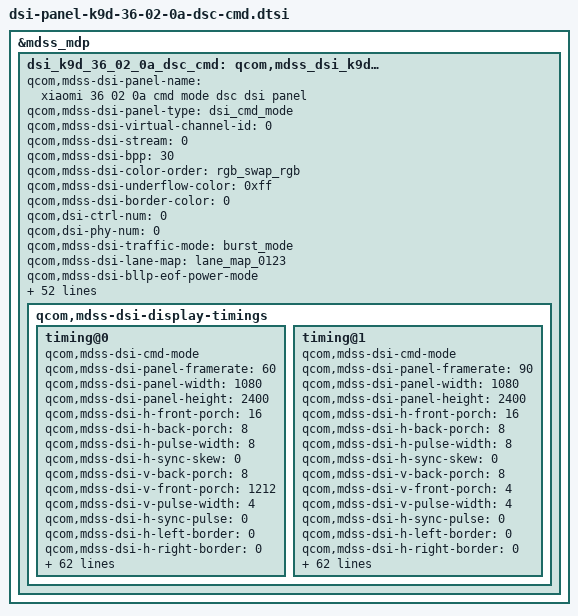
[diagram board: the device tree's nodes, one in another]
&mdss_mdp {
	dsi_k9d_36_02_0a_dsc_cmd: qcom,mdss_dsi_k9d_36_02_0a_dsc_cmd {
		qcom,mdss-dsi-panel-name = "xiaomi 36 02 0a cmd mode dsc dsi panel";
		qcom,mdss-dsi-panel-type = "dsi_cmd_mode";
		qcom,mdss-dsi-virtual-channel-id = <0>;
		qcom,mdss-dsi-stream = <0>;
		qcom,mdss-dsi-bpp = <30>;
		qcom,mdss-dsi-color-order = "rgb_swap_rgb";
		qcom,mdss-dsi-underflow-color = <0xff>;
		qcom,mdss-dsi-border-color = <0>;

		qcom,dsi-ctrl-num = <0>;
		qcom,dsi-phy-num = <0>;

		qcom,mdss-dsi-traffic-mode = "burst_mode";
		qcom,mdss-dsi-lane-map = "lane_map_0123";
		qcom,mdss-dsi-bllp-eof-power-mode;
		qcom,mdss-dsi-bllp-power-mode;
		qcom,mdss-dsi-lane-0-state;
		qcom,mdss-dsi-lane-1-state;
		qcom,mdss-dsi-lane-2-state;
		qcom,mdss-dsi-lane-3-state;
		qcom,mdss-dsi-dma-trigger = "trigger_sw";
		qcom,mdss-dsi-mdp-trigger = "none";
		qcom,mdss-dsi-reset-sequence =  <1 11>, <0 1>, <1 11>;
		qcom,mdss-pan-physical-width-dimension = <683>;
		qcom,mdss-pan-physical-height-dimension = <1517>;
		qcom,mdss-dsi-te-pin-select = <1>;
		qcom,mdss-dsi-wr-mem-start = <0x2c>;
		qcom,mdss-dsi-wr-mem-continue = <0x3c>;
		qcom,mdss-dsi-te-dcs-command = <1>;
		qcom,mdss-dsi-te-check-enable;
		qcom,mdss-dsi-te-using-te-pin;
		qcom,mdss-dsi-tx-eot-append;
		qcom,mdss-dsi-lp11-init;

		qcom,mdss-dsi-bl-inverted-dbv;
		qcom,bl-update-flag = "delay_until_first_frame";

		qcom,mdss-dsi-panel-hdr-enabled;
		qcom,mdss-dsi-panel-hdr-color-primaries = <14500 15500 32000 17000 15500 30000 8000 3000>;
		qcom,mdss-dsi-panel-peak-brightness = <4200000>;
		qcom,mdss-dsi-panel-blackness-level = <3230>;

		qcom,mdss-dsi-display-timings {
			timing@0{
				qcom,mdss-dsi-cmd-mode;
				qcom,mdss-dsi-panel-framerate = <60>;
				qcom,mdss-dsi-panel-width = <1080>;
				qcom,mdss-dsi-panel-height = <2400>;
				qcom,mdss-dsi-h-front-porch = <16>;
				qcom,mdss-dsi-h-back-porch = <8>;
				qcom,mdss-dsi-h-pulse-width = <8>;
				qcom,mdss-dsi-h-sync-skew = <0>;
				qcom,mdss-dsi-v-back-porch = <8>;
				qcom,mdss-dsi-v-front-porch = <1212>;
				qcom,mdss-dsi-v-pulse-width = <4>;
				qcom,mdss-dsi-h-sync-pulse = <0>;
				qcom,mdss-dsi-h-left-border = <0>;
				qcom,mdss-dsi-h-right-border = <0>;
				qcom,mdss-dsi-v-top-border = <0>;
				qcom,mdss-dsi-v-bottom-border = <0>;
				qcom,mdss-dsi-panel-clockrate = <682000000>;
				qcom,mdss-dsi-panel-jitter = <0x5 0x1>;
				qcom,mdss-mdp-transfer-time-us = <15700>;
				qcom,mdss-dsi-on-command = [
					/* Command Mode */
					39 01 00 00 00 00 06 F0 55 AA 52 08 00
					/* video trim */
					39 00 00 00 00 00 09 BA 01 E6 00 10 00 30 00 01
					15 00 00 00 00 00 02 B2 58
					15 00 00 00 00 00 02 6F 02
					/* 60Hz dimming speed: 12 frames*/
					39 00 00 00 00 00 03 B2 0C 0C
					/* ESD/MIPI Error Flag, Low when Error Happen */
					39 00 00 00 00 00 05 BE 0E 0B 14 13
					15 00 00 00 00 00 02 6F 05
					15 00 00 00 00 00 02 BE 8A
					15 00 00 00 00 00 02 C0 66
					15 00 00 00 00 00 02 6F 08
					15 01 00 00 00 00 02 B5 32
					/* Round Corner ON */
					39 00 00 00 00 00 06 F0 55 AA 52 08 07
					39 01 00 00 00 00 02 C0 01
					/* Adjustment of left corner */
					39 00 00 00 00 00 2C C1 30 0F 04 C9 0F 81 EE C6 3F FB B3 6A 3F F6 D1 42 80 00
					F7 33 B1 00 18 00 00 8B 23 33 C0 0F B9 0F DD 8D 00 00 00 0D 08 00 17 23 00
					39 00 00 00 00 00 2C C2 38 0F 0B 64 02 11 F6 4C 3F FA E2 14 FF FE 41 A8 00 00
					5E 26 90 00 00 24 00 17 90 33 C0 09 B4 0F 94 E9 00 00 90 0D 3C 90 17 57 00
					39 00 00 00 00 00 2C C3 3C 00 04 C9 0F 81 11 3A 3F F9 58 7C 00 04 F1 78 00 00
					00 00 00 90 18 3C 90 8B 5F 33 60 00 00 0C DD 73 00 00 04 20 08 04 2A 23 00
					39 01 00 00 00 00 2C C4 3C 00 0B 64 02 11 09 B4 3F F6 CA 24 C0 00 00 00 00 00
					00 00 00 80 00 CF 90 17 3B 33 C0 00 00 0C 94 17 00 00 94 20 3C 94 2A 57 00
					39 00 00 00 00 00 2C C5 26 00 04 C9 0F 81 11 3A 00 00 00 00 3F EF 14 34 80 00
					00 00 00 03 AC 00 04 1F 23 33 C0 00 00 03 23 8D 00 00 00 00 00 00 00 00 00
					39 00 00 00 00 00 2C C6 2E 00 0B 64 02 11 09 B4 00 03 11 F4 FF FD 62 7C 00 00
					00 00 00 04 20 24 04 37 90 33 C0 00 00 03 6C E9 00 00 00 00 00 00 00 00 00
					39 00 00 00 00 00 2C C7 2A 0F 04 C9 0F 81 EE C6 00 02 5A EE 00 0C AE 86 7F FD
					F9 F3 65 93 AC 3C 94 1F 5F 33 6F F0 47 00 23 73 00 00 00 00 00 00 00 00 00
					39 01 00 00 00 00 2C C8 2A 0F 0B 64 02 11 F6 4C 00 07 29 E4 C0 00 DF 2C 7F FF
					43 B2 E0 84 20 CF 94 37 3B 33 CF F6 4C 00 6C 17 00 00 00 00 00 00 00 00 00
					39 00 00 00 00 00 2C C9 27 00 03 C1 04 41 00 00 00 00 00 00 3F FE F8 42 00 00
					00 00 00 00 63 24 00 84 43 33 90 00 00 03 1F DF 00 00 00 00 00 00 00 00 00
					39 00 00 00 00 00 2C CA 21 00 03 C1 04 00 00 00 3F FF 0F C0 3F FF 08 00 00 00
					0F 04 00 00 42 24 00 62 43 33 90 03 E0 0F E1 E0 00 00 00 00 00 00 00 00 00
					39 00 00 00 00 00 2C CB 2D 00 04 00 04 00 00 00 3F FF 00 00 00 00 00 00 80 00
					00 00 00 00 42 44 00 62 64 33 60 00 00 0C E0 20 00 00 00 00 00 00 00 00 00
					39 01 00 00 00 00 2C CC 2B 00 04 00 04 41 00 00 00 00 00 00 00 00 00 00 FF FF
					EE FC 00 00 63 44 00 84 64 33 6F FB E0 00 20 21 00 00 00 00 00 00 00 00 00
					/* Adjustment of buttom line color */
					15 00 00 00 00 00 02 B4 C0
					15 00 00 00 00 00 02 6F 01
					39 01 00 00 00 00 04 B4 00 80 80
					/* Page 1 */
					39 01 00 00 00 00 06 F0 55 AA 52 08 01
					39 00 00 00 00 00 02 6F 01
					39 00 00 00 00 00 04 D2 00 00 11
					39 00 00 00 00 00 02 6F 06
					39 00 00 00 00 00 02 D2 05
					39 00 00 00 00 00 02 6F 0F
					39 00 00 00 00 00 02 D2 00
					//U_ELVDD discharge
					39 00 00 00 00 00 02 6F 09
					39 00 00 00 00 00 03 D2 00 00
					// U_ELVDD/U_ELVSS FD disable , AVDD FD enable
					39 00 00 00 00 00 02 CE 00
					//cmd3: aod no black
					39 00 00 00 00 00 05 FF AA 55 A5 80
					39 00 00 00 00 00 02 6F 61
					39 00 00 00 00 00 02 F3 80
					/* Page 0 */
					39 00 00 00 00 00 06 F0 55 AA 52 08 00
					39 00 00 00 00 00 02 C0 46
					//esd normal high without mipi error
					39 00 00 00 00 00 03 BE 0E 0B
					39 00 00 00 00 00 02 6F 05
					39 00 00 00 00 00 02 BE 88
					//PMIC normal FD en
					39 00 00 00 00 00 02 6F 08
					39 00 00 00 00 00 02 B5 32
					//PMIC AOD FD disable
					39 00 00 00 00 00 02 6F 0B
					39 00 00 00 00 00 04 B5 33 23 2B
					39 00 00 00 00 00 06 F0 55 AA 52 08 01
					39 00 00 00 00 00 04 D1 07 00 04
					39 00 00 00 00 00 05 3B 00 10 00 30
					/* Reduce source OP chopper offset */
					39 00 00 00 00 00 02 D9 C8
					/* VESA ON */
					15 01 00 00 00 00 02 90 01
					/* Choose VESA Edition */
					39 00 00 00 00 00 13 91
						AB 28 00 0C C2 00 03 1C 01 7E
						00 0F 08 BB 04 3D 10 F0
					/* DSC Setting */
					15 00 00 00 00 00 02 03 01
					/* Backlight */
					39 00 00 00 00 00 05 51 00 00 00 00
					/* Dimming on */
					15 00 00 00 00 00 02 53 20
					/* TE ON */
					15 00 00 00 00 00 02 35 00
					39 00 00 00 00 00 05 2A 00 00 04 37
					39 00 00 00 00 00 05 2B 00 00 09 5F
					/* Enter 60hz */
					15 01 00 00 00 00 02 2F 02
					/* OSC=109.2MHz */
					39 00 00 00 00 00 05 FF AA 55 A5 81
					15 00 00 00 00 00 02 6F 0F
					39 00 00 00 00 00 03 FD 01 5A
					/* OSC boost code */
					15 00 00 00 00 00 02 6F 04
					15 00 00 00 00 00 02 FD 5F
					15 00 00 00 00 00 02 6F 1A
					15 00 00 00 00 00 02 FD 5F
					05 01 00 00 00 00 01 2C
					/* Speed up code */
					39 00 00 00 00 00 06 F0 55 AA 52 08 00
					39 00 00 00 00 00 05 CA 12 00 92 02
					15 00 00 00 00 00 02 6F 02
					39 00 00 00 00 00 03 EC 80 10
					39 00 00 00 00 00 06 F0 55 AA 52 08 01
					39 00 00 00 00 00 03 CD 05 31
					15 00 00 00 00 00 02 6F 10
					15 00 00 00 00 00 02 D8 0C
					39 00 00 00 00 00 06 F0 55 AA 52 08 05
					39 00 00 00 00 00 03 B3 86 80
					39 00 00 00 00 00 03 B5 85 81
					39 00 00 00 00 00 05 B7 85 00 00 81
					39 00 00 00 00 00 05 B8 05 00 00 81
					39 00 00 00 00 00 03 EC 0D 11
					15 00 00 00 00 00 02 6F 02
					39 01 00 00 00 00 13 EC
						00 00 00 00 00 00 00 00 00 00
						00 00 00 00 00 00 00 00
					39 01 00 00 00 00 06 F0 55 AA 52 08 00
					//PMIC normal FD en
					39 01 00 00 00 00 02 6F 08
					39 01 00 00 00 00 02 B5 32
					//PMIC AOD FD disable
					39 01 00 00 00 00 02 6F 0B
					39 01 00 00 00 00 04 B5 33 23 2B
					39 01 00 00 00 00 06 F0 55 AA 52 08 01
					// U_ELVDD/U_ELVSS FD disable , AVDD FD disable
					39 01 00 00 00 00 02 CE 00
					/* Set page 1 */
					39 00 00 00 00 00 06 F0 55 AA 52 08 01
					/* Video trim */
					39 00 00 00 00 00 08 C3 94 01 97 D0 22 02 00
					/* Sleep Out */
					05 01 00 00 32 00 02 11 00
					/* Display On */
					05 01 00 00 10 00 02 29 00];
				qcom,mdss-dsi-off-command = [
					05 01 00 00 14 00 02 28 00
					05 01 00 00 50 00 02 10 00];
				qcom,mdss-dsi-on-command-state = "dsi_lp_mode";
				qcom,mdss-dsi-off-command-state = "dsi_lp_mode";

				qcom,mdss-dsi-timing-switch-command = [
					15 01 00 00 00 00 02 2F 02];
				qcom,mdss-dsi-timing-switch-command-state = "dsi_lp_mode";

				qcom,mdss-dsi-nolp-command = [
					15 01 00 00 00 00 02 65 00
					05 01 00 00 07 00 01 38
					39 01 00 00 00 00 06 F0 55 AA 52 08 01
					39 01 00 00 1B 00 05 BA 10 1A 10 1A
					39 01 00 00 00 00 05 BA 10 10 10 10
					15 01 00 00 00 00 02 2F 02];
				qcom,mdss-dsi-nolp-command-state = "dsi_lp_mode";

				qcom,compression-mode = "dsc";
				qcom,mdss-dsc-version = <0x11>;
				qcom,mdss-dsc-scr-version = <0x0>;
				qcom,mdss-dsc-slice-height = <12>;
				qcom,mdss-dsc-slice-width = <1080>;
				qcom,mdss-dsc-slice-per-pkt = <1>;
				qcom,mdss-dsc-bit-per-component = <10>;
				qcom,mdss-dsc-bit-per-pixel = <8>;
				qcom,mdss-dsc-block-prediction-enable;
			};

			timing@1{
				qcom,mdss-dsi-cmd-mode;
				qcom,mdss-dsi-panel-framerate = <90>;
				qcom,mdss-dsi-panel-width = <1080>;
				qcom,mdss-dsi-panel-height = <2400>;
				qcom,mdss-dsi-h-front-porch = <16>;
				qcom,mdss-dsi-h-back-porch = <8>;
				qcom,mdss-dsi-h-pulse-width = <8>;
				qcom,mdss-dsi-h-sync-skew = <0>;
				qcom,mdss-dsi-v-back-porch = <8>;
				qcom,mdss-dsi-v-front-porch = <4>;
				qcom,mdss-dsi-v-pulse-width = <4>;
				qcom,mdss-dsi-h-sync-pulse = <0>;
				qcom,mdss-dsi-h-left-border = <0>;
				qcom,mdss-dsi-h-right-border = <0>;
				qcom,mdss-dsi-v-top-border = <0>;
				qcom,mdss-dsi-v-bottom-border = <0>;
				qcom,mdss-dsi-panel-clockrate = <682000000>;
				qcom,mdss-dsi-panel-jitter = <0x5 0x1>;
				qcom,mdss-mdp-transfer-time-us = <9500>;
				qcom,mdss-dsi-on-command = [
					/* Command Mode */
					39 01 00 00 00 00 06 F0 55 AA 52 08 00
					/* video trim */
					39 00 00 00 00 00 09 BA 01 E6 00 10 00 30 00 01
					15 00 00 00 00 00 02 B2 58
					15 00 00 00 00 00 02 6F 02
					/* 90Hz dimming speed: 18 frames*/
					39 00 00 00 00 00 03 B2 12 12
					/* ESD/MIPI Error Flag, Low when Error Happen */
					39 00 00 00 00 00 05 BE 0E 0B 14 13
					15 00 00 00 00 00 02 6F 05
					15 00 00 00 00 00 02 BE 8A
					15 00 00 00 00 00 02 C0 66
					15 00 00 00 00 00 02 6F 08
					15 00 00 00 00 00 02 B5 32
					/* Round Corner ON */
					39 00 00 00 00 00 06 F0 55 AA 52 08 07
					39 01 00 00 00 00 02 C0 01
					/* Adjustment of left corner */
					39 00 00 00 00 00 2C C1 30 0F 04 C9 0F 81 EE C6 3F FB B3 6A 3F F6 D1 42 80 00
					F7 33 B1 00 18 00 00 8B 23 33 C0 0F B9 0F DD 8D 00 00 00 0D 08 00 17 23 00
					39 00 00 00 00 00 2C C2 38 0F 0B 64 02 11 F6 4C 3F FA E2 14 FF FE 41 A8 00 00
					5E 26 90 00 00 24 00 17 90 33 C0 09 B4 0F 94 E9 00 00 90 0D 3C 90 17 57 00
					39 00 00 00 00 00 2C C3 3C 00 04 C9 0F 81 11 3A 3F F9 58 7C 00 04 F1 78 00 00
					00 00 00 90 18 3C 90 8B 5F 33 60 00 00 0C DD 73 00 00 04 20 08 04 2A 23 00
					39 01 00 00 00 00 2C C4 3C 00 0B 64 02 11 09 B4 3F F6 CA 24 C0 00 00 00 00 00
					00 00 00 80 00 CF 90 17 3B 33 C0 00 00 0C 94 17 00 00 94 20 3C 94 2A 57 00
					39 00 00 00 00 00 2C C5 26 00 04 C9 0F 81 11 3A 00 00 00 00 3F EF 14 34 80 00
					00 00 00 03 AC 00 04 1F 23 33 C0 00 00 03 23 8D 00 00 00 00 00 00 00 00 00
					39 00 00 00 00 00 2C C6 2E 00 0B 64 02 11 09 B4 00 03 11 F4 FF FD 62 7C 00 00
					00 00 00 04 20 24 04 37 90 33 C0 00 00 03 6C E9 00 00 00 00 00 00 00 00 00
					39 00 00 00 00 00 2C C7 2A 0F 04 C9 0F 81 EE C6 00 02 5A EE 00 0C AE 86 7F FD
					F9 F3 65 93 AC 3C 94 1F 5F 33 6F F0 47 00 23 73 00 00 00 00 00 00 00 00 00
					39 01 00 00 00 00 2C C8 2A 0F 0B 64 02 11 F6 4C 00 07 29 E4 C0 00 DF 2C 7F FF
					43 B2 E0 84 20 CF 94 37 3B 33 CF F6 4C 00 6C 17 00 00 00 00 00 00 00 00 00
					39 00 00 00 00 00 2C C9 27 00 03 C1 04 41 00 00 00 00 00 00 3F FE F8 42 00 00
					00 00 00 00 63 24 00 84 43 33 90 00 00 03 1F DF 00 00 00 00 00 00 00 00 00
					39 00 00 00 00 00 2C CA 21 00 03 C1 04 00 00 00 3F FF 0F C0 3F FF 08 00 00 00
					0F 04 00 00 42 24 00 62 43 33 90 03 E0 0F E1 E0 00 00 00 00 00 00 00 00 00
					39 00 00 00 00 00 2C CB 2D 00 04 00 04 00 00 00 3F FF 00 00 00 00 00 00 80 00
					00 00 00 00 42 44 00 62 64 33 60 00 00 0C E0 20 00 00 00 00 00 00 00 00 00
					39 01 00 00 00 00 2C CC 2B 00 04 00 04 41 00 00 00 00 00 00 00 00 00 00 FF FF
					EE FC 00 00 63 44 00 84 64 33 6F FB E0 00 20 21 00 00 00 00 00 00 00 00 00
					/* Adjustment of buttom line color */
					15 00 00 00 00 00 02 B4 C0
					15 00 00 00 00 00 02 6F 01
					39 01 00 00 00 00 04 B4 00 80 80
					/* Page 1 */
					39 01 00 00 00 00 06 F0 55 AA 52 08 01
					39 00 00 00 00 00 02 6F 01
					39 00 00 00 00 00 04 D2 00 00 11
					39 00 00 00 00 00 02 6F 06
					39 00 00 00 00 00 02 D2 05
					39 00 00 00 00 00 02 6F 0F
					39 00 00 00 00 00 02 D2 00
					//U_ELVDD discharge
					39 00 00 00 00 00 02 6F 09
					39 00 00 00 00 00 03 D2 00 00
					// U_ELVDD/U_ELVSS FD disable , AVDD FD enable
					39 00 00 00 00 00 02 CE 00
					//cmd3: aod no black
					39 00 00 00 00 00 05 FF AA 55 A5 80
					39 00 00 00 00 00 02 6F 61
					39 00 00 00 00 00 02 F3 80
					/* Page 0 */
					39 00 00 00 00 00 06 F0 55 AA 52 08 00
					39 00 00 00 00 00 02 C0 46
					//esd normal high without mipi error
					39 00 00 00 00 00 03 BE 0E 0B
					39 00 00 00 00 00 02 6F 05
					39 00 00 00 00 00 02 BE 88
					//PMIC normal FD en
					39 00 00 00 00 00 02 6F 08
					39 00 00 00 00 00 02 B5 32
					//PMIC AOD FD disable
					39 00 00 00 00 00 02 6F 0B
					39 00 00 00 00 00 04 B5 33 23 2B
					39 00 00 00 00 00 06 F0 55 AA 52 08 01
					39 00 00 00 00 00 04 D1 07 00 04
					39 00 00 00 00 00 05 3B 00 10 00 30
					/* Reduce source OP chopper offset */
					39 00 00 00 00 00 02 D9 C8
					/* VESA ON */
					15 01 00 00 00 00 02 90 01
					/* Choose VESA Edition */
					39 00 00 00 00 00 13 91
						AB 28 00 0C C2 00 03 1C 01 7E
						00 0F 08 BB 04 3D 10 F0
					/* DSC setting */
					15 00 00 00 00 00 02 03 01
					/* Backlight */
					39 00 00 00 00 00 05 51 00 00 00 00
					/* Dimming On */
					15 00 00 00 00 00 02 53 20
					/* TE ON */
					15 00 00 00 00 00 02 35 00
					39 00 00 00 00 00 05 2A 00 00 04 37
					39 00 00 00 00 00 05 2B 00 00 09 5F
					/* Enter 90HZ */
					15 01 00 00 00 00 02 2F 01
					/* OSC=109.2MHz */
					39 00 00 00 00 00 05 FF AA 55 A5 81
					15 00 00 00 00 00 02 6F 0F
					39 00 00 00 00 00 03 FD 01 5A
					/* OSC boost code */
					15 00 00 00 00 00 02 6F 04
					15 00 00 00 00 00 02 FD 5F
					15 00 00 00 00 00 02 6F 1A
					15 00 00 00 00 00 02 FD 5F
					05 01 00 00 00 00 01 2C
					/* Speed up code */
					39 00 00 00 00 00 06 F0 55 AA 52 08 00
					39 00 00 00 00 00 05 CA 12 00 92 02
					15 00 00 00 00 00 02 6F 02
					39 00 00 00 00 00 03 EC 80 10
					39 00 00 00 00 00 06 F0 55 AA 52 08 01
					39 00 00 00 00 00 03 CD 05 31
					15 00 00 00 00 00 02 6F 10
					15 00 00 00 00 00 02 D8 0C
					39 00 00 00 00 00 06 F0 55 AA 52 08 05
					39 00 00 00 00 00 03 B3 86 80
					39 00 00 00 00 00 03 B5 85 81
					39 00 00 00 00 00 05 B7 85 00 00 81
					39 00 00 00 00 00 05 B8 05 00 00 81
					39 00 00 00 00 00 03 EC 0D 11
					15 00 00 00 00 00 02 6F 02
					39 01 00 00 00 00 13 EC
						00 00 00 00 00 00 00 00 00 00
						00 00 00 00 00 00 00 00
					39 01 00 00 00 00 06 F0 55 AA 52 08 00
					//PMIC normal FD en
					39 01 00 00 00 00 02 6F 08
					39 01 00 00 00 00 02 B5 32
					//PMIC AOD FD disable
					39 01 00 00 00 00 02 6F 0B
					39 01 00 00 00 00 04 B5 33 23 2B
					39 01 00 00 00 00 06 F0 55 AA 52 08 01
					// U_ELVDD/U_ELVSS FD disable , AVDD FD disable
					39 01 00 00 00 00 02 CE 00
					/* Set page 1 */
					39 00 00 00 00 00 06 F0 55 AA 52 08 01
					/* Video trim */
					39 00 00 00 00 00 08 C3 94 01 97 D0 22 02 00
					/* Sleep Out */
					05 01 00 00 32 00 02 11 00
					/* Display On */
					05 01 00 00 10 00 02 29 00];
				qcom,mdss-dsi-off-command = [
					05 01 00 00 14 00 02 28 00
					05 01 00 00 50 00 02 10 00];
				qcom,mdss-dsi-on-command-state = "dsi_lp_mode";
				qcom,mdss-dsi-off-command-state = "dsi_lp_mode";

				qcom,mdss-dsi-timing-switch-command = [
					15 01 00 00 00 00 02 2F 01];
				qcom,mdss-dsi-timing-switch-command-state = "dsi_lp_mode";

				qcom,mdss-dsi-nolp-command = [
					15 01 00 00 00 00 02 65 00
					05 01 00 00 07 00 01 38
					39 00 00 00 00 00 06 F0 55 AA 52 08 01
					39 01 00 00 1B 00 05 BA 10 1A 10 1A
					39 01 00 00 00 00 05 BA 10 10 10 10
					15 01 00 00 00 00 02 2F 01];
				qcom,mdss-dsi-nolp-command-state = "dsi_lp_mode";

				qcom,compression-mode = "dsc";
				qcom,mdss-dsc-version = <0x11>;
				qcom,mdss-dsc-scr-version = <0x0>;
				qcom,mdss-dsc-slice-height = <12>;
				qcom,mdss-dsc-slice-width = <1080>;
				qcom,mdss-dsc-slice-per-pkt = <1>;
				qcom,mdss-dsc-bit-per-component = <10>;
				qcom,mdss-dsc-bit-per-pixel = <8>;
				qcom,mdss-dsc-block-prediction-enable;
			};
		};
	};
};

&dsi_k9d_36_02_0a_dsc_cmd {
	mi,panel-id = <0x004B3944 0x00360200>;
	mi,hbm-51-ctl-flag;
	mi,hbm-off-51-index = <1>;
	mi,hbm-on-51-index = <1>;
	mi,hbm-bl-min-level = <1>;
	mi,hbm-bl-max-level = <2047>;
	mi,panel-on-dimming-delay = <120>;
	mi,max-brightness-clone = <4095>;
	mi,fp-display-on-optimize-flag;
	mi,thermal-dimming-flag;
	mi,timming-switch-wait-for-te-flag;

	/* IRQF_ONESHOT | IRQF_TRIGGER_FALLING */
	mi,esd-err-irq-gpio = <&tlmm 3 0x2002>;

	mi,panel-aod-to-off-command-need-enabled;

	qcom,esd-check-enabled;
	qcom,esd-aod-check-enabled;
	qcom,mdss-dsi-panel-status-check-mode = "reg_read";
	qcom,mdss-dsi-panel-status-offset-command = [
		39 01 00 00 00 00 05 FF AA 55 A5 81
		15 01 00 00 00 00 02 6F 0F];
	qcom,mdss-dsi-panel-status-command = [06 01 00 00 00 00 01 FA];
	qcom,mdss-dsi-panel-status-command-state = "dsi_lp_mode";
	qcom,mdss-dsi-panel-status-offset-command-state = "dsi_lp_mode";
	qcom,mdss-dsi-panel-status-value = <0x00>;
	qcom,mdss-dsi-panel-status-read-length = <1>;

	qcom,mdss-dsi-display-timings {
		timing@0{
			mi,mdss-dsc-panel-id = <0x004B3944 0x00360200>;
			mi,mdss-dsi-dimmingon-command = [15 01 00 00 00 00 02 53 28];
			mi,mdss-dsi-dimmingon-command-state = "dsi_hs_mode";
			mi,mdss-dsi-dimmingoff-command = [15 01 00 00 00 00 02 53 20];
			mi,mdss-dsi-dimmingoff-command-state = "dsi_hs_mode";

			mi,mdss-dsi-hbm-on-command = [
				15 01 00 00 00 00 02 53 28
				39 01 00 00 00 00 05 51 0F FF 00 00];
			mi,mdss-dsi-hbm-off-command = [
				15 01 00 00 00 00 02 53 28
				39 01 00 00 00 00 05 51 07 FF 00 00];
			mi,mdss-dsi-hbm-on-command-state = "dsi_lp_mode";
			mi,mdss-dsi-hbm-off-command-state = "dsi_lp_mode";

			mi,mdss-dsi-doze-hbm-command = [
				15 01 00 00 00 00 02 2F 01
				15 01 00 00 00 00 02 6F 02
				39 01 00 00 00 00 03 51 03 FF
				05 01 00 00 14 00 01 39
				15 01 00 00 00 00 02 65 01];
			mi,mdss-dsi-doze-lbm-command = [
				15 01 00 00 00 00 02 2F 01
				15 01 00 00 00 00 02 6F 02
				39 01 00 00 00 00 03 51 01 FF
				05 01 00 00 14 00 01 39
				15 01 00 00 00 00 02 65 01];
			mi,mdss-dsi-doze-hbm-command-state = "dsi_lp_mode";
			mi,mdss-dsi-doze-lbm-command-state = "dsi_lp_mode";

			mi,mdss-dsi-flat-mode-on-command = [
				39 01 00 00 00 00 06 F0 55 AA 52 08 08
				15 01 00 00 00 00 02 B9 01];
			mi,mdss-dsi-flat-mode-off-command = [
				39 01 00 00 00 00 06 F0 55 AA 52 08 08
				15 01 00 00 00 00 02 B9 00];
			mi,mdss-dsi-flat-mode-on-command-state = "dsi_lp_mode";
			mi,mdss-dsi-flat-mode-off-command-state = "dsi_lp_mode";

			mi,mdss-dsi-pre-doze-to-off-command = [
				39 00 00 00 00 00 06 F0 55 AA 52 08 01
				39 01 00 00 00 00 02 CE 0C];
			mi,mdss-dsi-pre-doze-to-off-command-state = "dsi_lp_mode";
		};

		timing@1{
			mi,mdss-dsc-panel-id = <0x004B3944 0x00360200>;
			mi,mdss-dsi-dimmingon-command = [15 01 00 00 00 00 02 53 28];
			mi,mdss-dsi-dimmingon-command-state = "dsi_hs_mode";
			mi,mdss-dsi-dimmingoff-command = [15 01 00 00 00 00 02 53 20];
			mi,mdss-dsi-dimmingoff-command-state = "dsi_hs_mode";

			mi,mdss-dsi-hbm-on-command = [
				15 01 00 00 00 00 02 53 28
				39 01 00 00 00 00 05 51 0F FF 00 00];
			mi,mdss-dsi-hbm-off-command = [
				15 01 00 00 00 00 02 53 28
				39 01 00 00 00 00 05 51 07 FF 00 00];
			mi,mdss-dsi-hbm-on-command-state = "dsi_lp_mode";
			mi,mdss-dsi-hbm-off-command-state = "dsi_lp_mode";

			mi,mdss-dsi-doze-hbm-command = [
				15 01 00 00 00 00 02 2F 01
				15 01 00 00 00 00 02 6F 02
				39 01 00 00 00 00 03 51 03 FF
				05 01 00 00 14 00 01 39
				15 01 00 00 00 00 02 65 01];
			mi,mdss-dsi-doze-lbm-command = [
				15 01 00 00 00 00 02 2F 01
				15 01 00 00 00 00 02 6F 02
				39 01 00 00 00 00 03 51 01 FF
				05 01 00 00 14 00 01 39
				15 01 00 00 00 00 02 65 01];
			mi,mdss-dsi-doze-hbm-command-state = "dsi_lp_mode";
			mi,mdss-dsi-doze-lbm-command-state = "dsi_lp_mode";

			mi,mdss-dsi-flat-mode-on-command = [
				39 01 00 00 00 00 06 F0 55 AA 52 08 08
				15 01 00 00 00 00 02 B9 01];
			mi,mdss-dsi-flat-mode-off-command = [
				39 01 00 00 00 00 06 F0 55 AA 52 08 08
				15 01 00 00 00 00 02 B9 00];
			mi,mdss-dsi-flat-mode-on-command-state = "dsi_lp_mode";
			mi,mdss-dsi-flat-mode-off-command-state = "dsi_lp_mode";

			mi,mdss-dsi-pre-doze-to-off-command = [
				39 00 00 00 00 00 06 F0 55 AA 52 08 01
				39 01 00 00 00 00 02 CE 0C];
			mi,mdss-dsi-pre-doze-to-off-command-state = "dsi_lp_mode";
		};
	};
};

